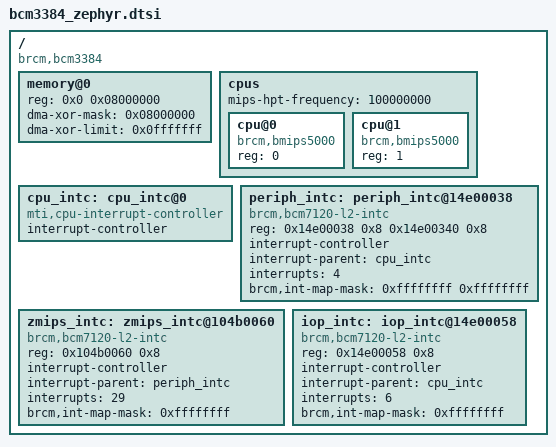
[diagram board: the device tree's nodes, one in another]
/include/ "bcm3384_common.dtsi"

/ {
	#address-cells = <1>;
	#size-cells = <1>;
	compatible = "brcm,bcm3384", "brcm,bcm33843";

	memory@0 {
		device_type = "memory";

		/* Typical range.  The bootloader should fill this in. */
		reg = <0x0 0x08000000>;

		/* Inverted mapping in low 256MB; 1:1 mapping above that. */
		dma-xor-mask = <0x08000000>;
		dma-xor-limit = <0x0fffffff>;
	};

	cpus {
		#address-cells = <1>;
		#size-cells = <0>;

		/* On BMIPS5000 this is 1/8th of the CPU core clock */
		mips-hpt-frequency = <100000000>;

		cpu@0 {
			compatible = "brcm,bmips5000";
			device_type = "cpu";
			reg = <0>;
		};

		cpu@1 {
			compatible = "brcm,bmips5000";
			device_type = "cpu";
			reg = <1>;
		};
	};

	cpu_intc: cpu_intc@0 {
		#address-cells = <0>;
		compatible = "mti,cpu-interrupt-controller";

		interrupt-controller;
		#interrupt-cells = <1>;
	};

	periph_intc: periph_intc@14e00038 {
		compatible = "brcm,bcm7120-l2-intc";
		reg = <0x14e00038 0x8 0x14e00340 0x8>;

		interrupt-controller;
		#interrupt-cells = <1>;

		interrupt-parent = <&cpu_intc>;
		interrupts = <4>;
		brcm,int-map-mask = <0xffffffff 0xffffffff>;
	};

	zmips_intc: zmips_intc@104b0060 {
		compatible = "brcm,bcm7120-l2-intc";
		reg = <0x104b0060 0x8>;

		interrupt-controller;
		#interrupt-cells = <1>;

		interrupt-parent = <&periph_intc>;
		interrupts = <29>;
		brcm,int-map-mask = <0xffffffff>;
	};

	iop_intc: iop_intc@14e00058 {
		compatible = "brcm,bcm7120-l2-intc";
		reg = <0x14e00058 0x8>;

		interrupt-controller;
		#interrupt-cells = <1>;

		interrupt-parent = <&cpu_intc>;
		interrupts = <6>;
		brcm,int-map-mask = <0xffffffff>;
	};
};
